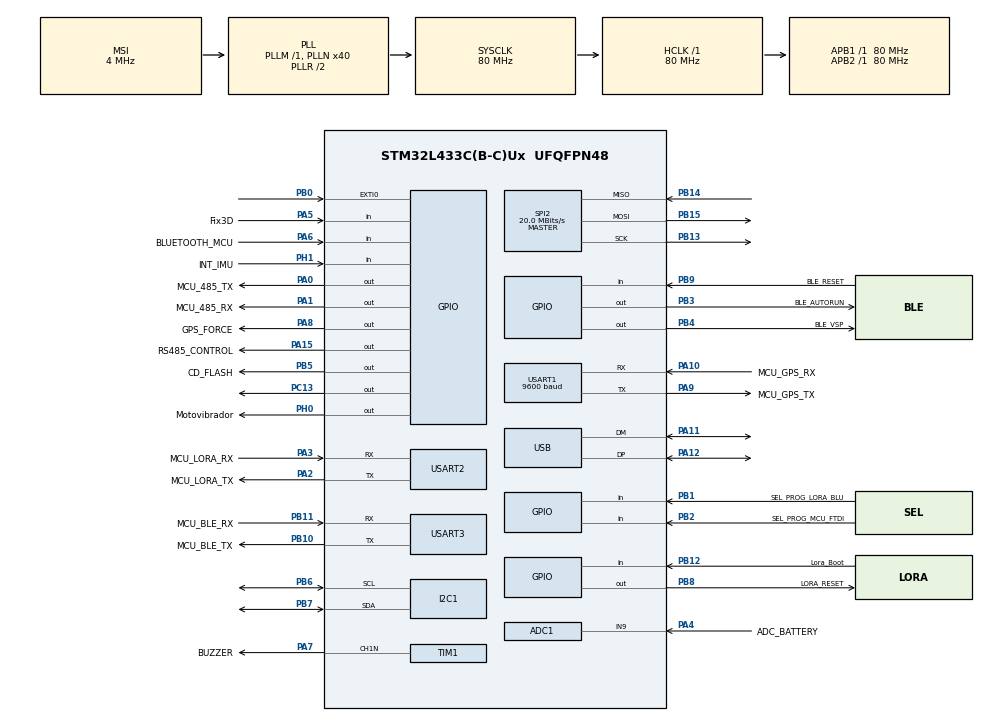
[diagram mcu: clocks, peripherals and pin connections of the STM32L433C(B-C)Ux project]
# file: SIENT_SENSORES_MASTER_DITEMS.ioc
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ADC1.Channel-1\#ChannelRegularConversion=ADC_CHANNEL_9
ADC1.NbrOfConversionFlag=1
ADC1.OffsetNumber-1\#ChannelRegularConversion=ADC_OFFSET_NONE
ADC1.Rank-1\#ChannelRegularConversion=1
ADC1.SamplingTime-1\#ChannelRegularConversion=ADC_SAMPLETIME_2CYCLES_5
ADC1.master=1
Dma.Request0=USART1_RX
Dma.Request1=USART2_RX
Dma.USART1_RX.0.Direction=DMA_PERIPH_TO_MEMORY
Dma.USART1_RX.0.Instance=DMA1_Channel5
Dma.USART1_RX.0.MemDataAlignment=DMA_MDATAALIGN_BYTE
Dma.USART1_RX.0.MemInc=DMA_MINC_ENABLE
Dma.USART1_RX.0.Mode=DMA_CIRCULAR
Dma.USART1_RX.0.PeriphDataAlignment=DMA_PDATAALIGN_BYTE
Dma.USART1_RX.0.PeriphInc=DMA_PINC_DISABLE
Dma.USART1_RX.0.Priority=DMA_PRIORITY_LOW
Dma.USART2_RX.1.Direction=DMA_PERIPH_TO_MEMORY
Dma.USART2_RX.1.Instance=DMA1_Channel6
Dma.USART2_RX.1.MemDataAlignment=DMA_MDATAALIGN_BYTE
Dma.USART2_RX.1.MemInc=DMA_MINC_ENABLE
Dma.USART2_RX.1.Mode=DMA_CIRCULAR
Dma.USART2_RX.1.PeriphDataAlignment=DMA_PDATAALIGN_BYTE
Dma.USART2_RX.1.PeriphInc=DMA_PINC_DISABLE
Dma.USART2_RX.1.Priority=DMA_PRIORITY_LOW
FREERTOS.Tasks01=defaultTask,24,128,StartDefaultTask,Default,NULL,Dynamic,NULL,NULL
FREERTOS.configTOTAL_HEAP_SIZE=16384
FREERTOS.configUSE_NEWLIB_REENTRANT=1
I2C1.Timing=0x10D19CE4
Mcu.Family=STM32L4
Mcu.Name=STM32L433C(B-C)Ux
Mcu.Package=UFQFPN48
NVIC.DMA1_Channel5_IRQn=true\:6\:0\:true\:false\:true\:true\:false\:true\:true
NVIC.DMA1_Channel6_IRQn=true\:5\:0\:false\:false\:true\:true\:false\:true\:true
NVIC.EXTI0_IRQn=true\:5\:0\:false\:false\:true\:false\:true\:true\:true
NVIC.PriorityGroup=NVIC_PRIORITYGROUP_4
NVIC.TIM7_IRQn=true\:15\:0\:false\:false\:true\:false\:false\:true\:true
NVIC.TimeBase=TIM7_IRQn
NVIC.TimeBaseIP=TIM7
NVIC.USART1_IRQn=true\:6\:0\:true\:false\:true\:true\:true\:true\:true
NVIC.USART2_IRQn=true\:5\:0\:false\:false\:true\:true\:true\:true\:true
NVIC.USART3_IRQn=true\:6\:0\:true\:false\:true\:true\:true\:true\:true
NVIC.USB_IRQn=true\:6\:0\:true\:false\:true\:true\:false\:true\:true
PA0.GPIO_Label=MCU_485_TX
PA0.Signal=GPIO_Output
PA1.GPIO_Label=MCU_485_RX
PA1.Signal=GPIO_Output
PA10.GPIO_Label=MCU_GPS_RX
PA10.Mode=Asynchronous
PA10.Signal=USART1_RX
PA11.Mode=Device
PA11.Signal=USB_DM
PA12.Mode=Device
PA12.Signal=USB_DP
PA13\ (JTMS-SWDIO).Mode=Serial_Wire
PA13\ (JTMS-SWDIO).Signal=SYS_JTMS-SWDIO
PA14\ (JTCK-SWCLK).Mode=Serial_Wire
PA14\ (JTCK-SWCLK).Signal=SYS_JTCK-SWCLK
PA15\ (JTDI).GPIO_Label=RS485_CONTROL
PA15\ (JTDI).Signal=GPIO_Output
PA2.GPIO_Label=MCU_LORA_TX
PA2.Mode=Asynchronous
PA2.Signal=USART2_TX
PA3.GPIO_Label=MCU_LORA_RX
PA3.Mode=Asynchronous
PA3.Signal=USART2_RX
PA4.GPIO_Label=ADC_BATTERY
PA4.Signal=ADCx_IN9
PA5.GPIO_Label=Fix3D
PA5.Signal=GPIO_Input
PA6.GPIO_Label=BLUETOOTH_MCU
PA6.Signal=GPIO_Input
PA7.GPIO_Label=BUZZER
PA7.Mode=PWM Generation1 CH1N
PA7.Signal=TIM1_CH1N
PA8.GPIO_Label=GPS_FORCE
PA8.Signal=GPIO_Output
PA9.GPIO_Label=MCU_GPS_TX
PA9.Mode=Asynchronous
PA9.Signal=USART1_TX
PB0.GPIO_ModeDefaultEXTI=GPIO_MODE_IT_RISING_FALLING
PB0.Signal=GPXTI0
PB1.GPIO_Label=SEL_PROG_LORA_BLU
PB1.Signal=GPIO_Input
PB10.GPIO_Label=MCU_BLE_TX
PB10.Mode=Asynchronous
PB10.Signal=USART3_TX
PB11.GPIO_Label=MCU_BLE_RX
PB11.Mode=Asynchronous
PB11.Signal=USART3_RX
PB12.GPIO_Label=Lora_Boot
PB12.Signal=GPIO_Input
PB13.Mode=Full_Duplex_Master
PB13.Signal=SPI2_SCK
PB14.Mode=Full_Duplex_Master
PB14.Signal=SPI2_MISO
PB15.Mode=Full_Duplex_Master
PB15.Signal=SPI2_MOSI
PB2.GPIO_Label=SEL_PROG_MCU_FTDI
PB2.Signal=GPIO_Input
PB3\ (JTDO-TRACESWO).GPIO_Label=BLE_AUTORUN
PB3\ (JTDO-TRACESWO).Signal=GPIO_Output
PB4\ (NJTRST).GPIO_Label=BLE_VSP
PB4\ (NJTRST).Signal=GPIO_Output
PB5.GPIO_Label=CD_FLASH
PB5.Signal=GPIO_Output
PB6.Mode=I2C
PB6.Signal=I2C1_SCL
PB7.Mode=I2C
PB7.Signal=I2C1_SDA
PB8.GPIO_Label=LORA_RESET
PB8.Signal=GPIO_Output
PB9.GPIO_Label=BLE_RESET
PB9.Signal=GPIO_Input
PC13.PinState=GPIO_PIN_SET
PC13.Signal=GPIO_Output
PC14-OSC32_IN\ (PC14).Mode=LSE-External-Oscillator
PC14-OSC32_IN\ (PC14).Signal=RCC_OSC32_IN
PC15-OSC32_OUT\ (PC15).Mode=LSE-External-Oscillator
PC15-OSC32_OUT\ (PC15).Signal=RCC_OSC32_OUT
PH0-OSC_IN\ (PH0).GPIO_Label=Motovibrador
PH0-OSC_IN\ (PH0).Signal=GPIO_Output
PH1-OSC_OUT\ (PH1).GPIO_Label=INT_IMU
PH1-OSC_OUT\ (PH1).Signal=GPIO_Input
ProjectManager.HeapSize=0x200
ProjectManager.StackSize=0x400
ProjectManager.TargetToolchain=STM32CubeIDE
RCC.ADCFreq_Value=48000000
RCC.AHBFreq_Value=80000000
RCC.APB1Freq_Value=80000000
RCC.APB1TimFreq_Value=80000000
RCC.APB2Freq_Value=80000000
RCC.APB2TimFreq_Value=80000000
RCC.CortexFreq_Value=80000000
RCC.HCLKFreq_Value=80000000
RCC.HSE_VALUE=8000000
RCC.HSI48_VALUE=48000000
RCC.HSI_VALUE=16000000
RCC.MSI_VALUE=4000000
RCC.PLLN=40
RCC.PLLSAI1N=24
RCC.SYSCLKFreq_VALUE=80000000
RCC.SYSCLKSource=RCC_SYSCLKSOURCE_PLLCLK
RCC.USBFreq_Value=48000000
RCC.VCOOutputFreq_Value=160000000
SH.ADCx_IN9.0=ADC1_IN9,IN9-Single-Ended
SPI2.BaudRatePrescaler=SPI_BAUDRATEPRESCALER_4
SPI2.CalculateBaudRate=20.0 MBits/s
SPI2.DataSize=SPI_DATASIZE_8BIT
SPI2.Direction=SPI_DIRECTION_2LINES
SPI2.Mode=SPI_MODE_MASTER
SPI2.VirtualType=VM_MASTER
TIM1.Channel-PWM\ Generation1\ CH1N=TIM_CHANNEL_1
TIM1.Prescaler=79
USART1.BaudRate=9600
USART1.VirtualMode-Asynchronous=VM_ASYNC
USART2.VirtualMode-Asynchronous=VM_ASYNC
USART3.VirtualMode-Asynchronous=VM_ASYNC
USB_DEVICE.CLASS_NAME_FS=CDC
USB_DEVICE.VirtualMode=Cdc
USB_DEVICE.VirtualModeFS=Cdc_FS
VP_FREERTOS_VS_CMSIS_V2.Mode=CMSIS_V2
VP_SYS_VS_tim7.Mode=TIM7
VP_TIM1_VS_ClockSourceINT.Mode=Internal
VP_USB_DEVICE_VS_USB_DEVICE_CDC_FS.Mode=CDC_FS
board=custom

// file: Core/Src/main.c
/* USER CODE BEGIN Header */
/**
  ******************************************************************************
  * @file           : main.c
  * @brief          : Main program body
  ******************************************************************************
  * @attention
  *
  * Copyright (c) 2026 STMicroelectronics.
  * All rights reserved.
  *
  * This software is licensed under terms that can be found in the LICENSE file
  * in the root directory of this software component.
  * If no LICENSE file comes with this software, it is provided AS-IS.
  *
  ******************************************************************************
  */
/* USER CODE END Header */
#include "main.h"
#include "cmsis_os.h"
#include "usb_device.h"

/* USER CODE BEGIN Includes */
#include "Inicializacion.h"
#include "Tareas.h"
#include "Test.h"
/* USER CODE END Includes */

ADC_HandleTypeDef hadc1;

I2C_HandleTypeDef hi2c1;

SPI_HandleTypeDef hspi2;

TIM_HandleTypeDef htim1;

UART_HandleTypeDef huart1;
UART_HandleTypeDef huart2;
UART_HandleTypeDef huart3;
DMA_HandleTypeDef hdma_usart1_rx;
DMA_HandleTypeDef hdma_usart2_rx;

void SystemClock_Config(void);
void PeriphCommonClock_Config(void);
static void MX_GPIO_Init(void);
static void MX_DMA_Init(void);
static void MX_ADC1_Init(void);
static void MX_I2C1_Init(void);
static void MX_SPI2_Init(void);
static void MX_TIM1_Init(void);
static void MX_USART1_UART_Init(void);
static void MX_USART2_UART_Init(void);
static void MX_USART3_UART_Init(void);

int main(void)
{

  /* MCU Configuration--------------------------------------------------------*/

  /* Reset of all peripherals, Initializes the Flash interface and the Systick. */
  HAL_Init();

  /* USER CODE BEGIN Init */

  /* DIAGNOSTICO: fuerza un reset completo del dominio RTC/backup al arrancar.
   * Sospecha: el pin WAKEUP del GPS (dominio RTC/Backup del modulo, ver
   * datasheet) se forzo en alto sostenido cuando debia quedar N/C — esta
   * tarjeta en particular dejo de poder entrar al bootloader USB de fabrica
   * (el Logger de la app SI sigue enumerando bien, pero ese usa un reloj USB
   * distinto al del bootloader ROM). Si el dominio backup de ESTE micro quedo
   * en un estado raro por esa maniobra, esto lo limpia. Quitar si no ayuda.
   */
  HAL_PWR_EnableBkUpAccess();
  __HAL_RCC_BACKUPRESET_FORCE();
  __HAL_RCC_BACKUPRESET_RELEASE();

  /* USER CODE END Init */

  /* Configure the system clock */
  SystemClock_Config();

  /* Configure the peripherals common clocks */
  PeriphCommonClock_Config();

  /* Initialize all configured peripherals */
  MX_GPIO_Init();
  MX_DMA_Init();
  MX_ADC1_Init();
  MX_I2C1_Init();
  MX_SPI2_Init();
  MX_TIM1_Init();
  MX_USART1_UART_Init();
  MX_USART2_UART_Init();
  MX_USART3_UART_Init();
  /* USER CODE BEGIN 2 */

  Inicializacion_Run();

  // Test_IR_Init();   /* PRUEBA IR — en pausa */

  /* USER CODE END 2 */

  /* Init scheduler */
  osKernelInitialize();

  /* USER CODE BEGIN RTOS_MUTEX */
  /* kernel inicializado, scheduler sin correr aun — seguro crear mutex aqui */
  Tareas_InicializarMutex();
  /* USER CODE END RTOS_MUTEX */

  /* Create the thread(s) */
  /* USER CODE BEGIN RTOS_THREADS */
  Tareas_CrearTareas();
  /* USER CODE END RTOS_THREADS */

  /* Start scheduler */
  osKernelStart();

  /* We should never get here as control is now taken by the scheduler */

  /* Infinite loop */
  while (1)
  {

    /* USER CODE BEGIN 3 */
    // Test_IR_Poll();   /* PRUEBA IR — en pausa */
  }
  /* USER CODE END 3 */
}

void SystemClock_Config(void)
{
  RCC_OscInitTypeDef RCC_OscInitStruct = {0};
  RCC_ClkInitTypeDef RCC_ClkInitStruct = {0};

  /** Configure the main internal regulator output voltage
  */
  if (HAL_PWREx_ControlVoltageScaling(PWR_REGULATOR_VOLTAGE_SCALE1) != HAL_OK)
  {
    Error_Handler();
  }

  /** Configure LSE Drive Capability
  */
  HAL_PWR_EnableBkUpAccess();
  __HAL_RCC_LSEDRIVE_CONFIG(RCC_LSEDRIVE_LOW);

  /** Initializes the RCC Oscillators according to the specified parameters
  * in the RCC_OscInitTypeDef structure.
  */
  RCC_OscInitStruct.OscillatorType = RCC_OSCILLATORTYPE_LSE|RCC_OSCILLATORTYPE_MSI;
  RCC_OscInitStruct.LSEState = RCC_LSE_ON;
  RCC_OscInitStruct.MSIState = RCC_MSI_ON;
  RCC_OscInitStruct.MSICalibrationValue = 0;
  RCC_OscInitStruct.MSIClockRange = RCC_MSIRANGE_6;
  RCC_OscInitStruct.PLL.PLLState = RCC_PLL_ON;
  RCC_OscInitStruct.PLL.PLLSource = RCC_PLLSOURCE_MSI;
  RCC_OscInitStruct.PLL.PLLM = 1;
  RCC_OscInitStruct.PLL.PLLN = 40;
  RCC_OscInitStruct.PLL.PLLP = RCC_PLLP_DIV7;
  RCC_OscInitStruct.PLL.PLLQ = RCC_PLLQ_DIV2;
  RCC_OscInitStruct.PLL.PLLR = RCC_PLLR_DIV2;
  if (HAL_RCC_OscConfig(&RCC_OscInitStruct) != HAL_OK)
  {
    Error_Handler();
  }

  /** Initializes the CPU, AHB and APB buses clocks
  */
  RCC_ClkInitStruct.ClockType = RCC_CLOCKTYPE_HCLK|RCC_CLOCKTYPE_SYSCLK
                              |RCC_CLOCKTYPE_PCLK1|RCC_CLOCKTYPE_PCLK2;
  RCC_ClkInitStruct.SYSCLKSource = RCC_SYSCLKSOURCE_PLLCLK;
  RCC_ClkInitStruct.AHBCLKDivider = RCC_SYSCLK_DIV1;
  RCC_ClkInitStruct.APB1CLKDivider = RCC_HCLK_DIV1;
  RCC_ClkInitStruct.APB2CLKDivider = RCC_HCLK_DIV1;

  if (HAL_RCC_ClockConfig(&RCC_ClkInitStruct, FLASH_LATENCY_4) != HAL_OK)
  {
    Error_Handler();
  }

  /** Enable MSI Auto calibration
  */
  HAL_RCCEx_EnableMSIPLLMode();
}

void PeriphCommonClock_Config(void)
{
  RCC_PeriphCLKInitTypeDef PeriphClkInit = {0};

  /** Initializes the peripherals clock
  */
  PeriphClkInit.PeriphClockSelection = RCC_PERIPHCLK_USB|RCC_PERIPHCLK_ADC;
  PeriphClkInit.AdcClockSelection = RCC_ADCCLKSOURCE_PLLSAI1;
  PeriphClkInit.UsbClockSelection = RCC_USBCLKSOURCE_PLLSAI1;
  PeriphClkInit.PLLSAI1.PLLSAI1Source = RCC_PLLSOURCE_MSI;
  PeriphClkInit.PLLSAI1.PLLSAI1M = 1;
  PeriphClkInit.PLLSAI1.PLLSAI1N = 24;
  PeriphClkInit.PLLSAI1.PLLSAI1P = RCC_PLLP_DIV7;
  PeriphClkInit.PLLSAI1.PLLSAI1Q = RCC_PLLQ_DIV2;
  PeriphClkInit.PLLSAI1.PLLSAI1R = RCC_PLLR_DIV2;
  PeriphClkInit.PLLSAI1.PLLSAI1ClockOut = RCC_PLLSAI1_48M2CLK|RCC_PLLSAI1_ADC1CLK;
  if (HAL_RCCEx_PeriphCLKConfig(&PeriphClkInit) != HAL_OK)
  {
    Error_Handler();
  }
}

static void MX_ADC1_Init(void)
{

  ADC_ChannelConfTypeDef sConfig = {0};

  /** Common config
  */
  hadc1.Instance = ADC1;
  hadc1.Init.ClockPrescaler = ADC_CLOCK_ASYNC_DIV1;
  hadc1.Init.Resolution = ADC_RESOLUTION_12B;
  hadc1.Init.DataAlign = ADC_DATAALIGN_RIGHT;
  hadc1.Init.ScanConvMode = ADC_SCAN_DISABLE;
  hadc1.Init.EOCSelection = ADC_EOC_SINGLE_CONV;
  hadc1.Init.LowPowerAutoWait = DISABLE;
  hadc1.Init.ContinuousConvMode = DISABLE;
  hadc1.Init.NbrOfConversion = 1;
  hadc1.Init.DiscontinuousConvMode = DISABLE;
  hadc1.Init.ExternalTrigConv = ADC_SOFTWARE_START;
  hadc1.Init.ExternalTrigConvEdge = ADC_EXTERNALTRIGCONVEDGE_NONE;
  hadc1.Init.DMAContinuousRequests = DISABLE;
  hadc1.Init.Overrun = ADC_OVR_DATA_PRESERVED;
  hadc1.Init.OversamplingMode = DISABLE;
  if (HAL_ADC_Init(&hadc1) != HAL_OK)
  {
    Error_Handler();
  }

  /** Configure Regular Channel
  */
  sConfig.Channel = ADC_CHANNEL_9;
  sConfig.Rank = ADC_REGULAR_RANK_1;
  sConfig.SamplingTime = ADC_SAMPLETIME_2CYCLES_5;
  sConfig.SingleDiff = ADC_SINGLE_ENDED;
  sConfig.OffsetNumber = ADC_OFFSET_NONE;
  sConfig.Offset = 0;
  if (HAL_ADC_ConfigChannel(&hadc1, &sConfig) != HAL_OK)
  {
    Error_Handler();
  }

}

static void MX_I2C1_Init(void)
{

  hi2c1.Instance = I2C1;
  hi2c1.Init.Timing = 0x10D19CE4;
  hi2c1.Init.OwnAddress1 = 0;
  hi2c1.Init.AddressingMode = I2C_ADDRESSINGMODE_7BIT;
  hi2c1.Init.DualAddressMode = I2C_DUALADDRESS_DISABLE;
  hi2c1.Init.OwnAddress2 = 0;
  hi2c1.Init.OwnAddress2Masks = I2C_OA2_NOMASK;
  hi2c1.Init.GeneralCallMode = I2C_GENERALCALL_DISABLE;
  hi2c1.Init.NoStretchMode = I2C_NOSTRETCH_DISABLE;
  if (HAL_I2C_Init(&hi2c1) != HAL_OK)
  {
    Error_Handler();
  }

  /** Configure Analogue filter
  */
  if (HAL_I2CEx_ConfigAnalogFilter(&hi2c1, I2C_ANALOGFILTER_ENABLE) != HAL_OK)
  {
    Error_Handler();
  }

  /** Configure Digital filter
  */
  if (HAL_I2CEx_ConfigDigitalFilter(&hi2c1, 0) != HAL_OK)
  {
    Error_Handler();
  }

}

static void MX_SPI2_Init(void)
{

  /* SPI2 parameter configuration*/
  hspi2.Instance = SPI2;
  hspi2.Init.Mode = SPI_MODE_MASTER;
  hspi2.Init.Direction = SPI_DIRECTION_2LINES;
  hspi2.Init.DataSize = SPI_DATASIZE_8BIT;
  hspi2.Init.CLKPolarity = SPI_POLARITY_LOW;
  hspi2.Init.CLKPhase = SPI_PHASE_1EDGE;
  hspi2.Init.NSS = SPI_NSS_SOFT;
  hspi2.Init.BaudRatePrescaler = SPI_BAUDRATEPRESCALER_4;
  hspi2.Init.FirstBit = SPI_FIRSTBIT_MSB;
  hspi2.Init.TIMode = SPI_TIMODE_DISABLE;
  hspi2.Init.CRCCalculation = SPI_CRCCALCULATION_DISABLE;
  hspi2.Init.CRCPolynomial = 7;
  hspi2.Init.CRCLength = SPI_CRC_LENGTH_DATASIZE;
  hspi2.Init.NSSPMode = SPI_NSS_PULSE_ENABLE;
  if (HAL_SPI_Init(&hspi2) != HAL_OK)
  {
    Error_Handler();
  }

}

static void MX_TIM1_Init(void)
{

  TIM_ClockConfigTypeDef sClockSourceConfig = {0};
  TIM_MasterConfigTypeDef sMasterConfig = {0};
  TIM_OC_InitTypeDef sConfigOC = {0};
  TIM_BreakDeadTimeConfigTypeDef sBreakDeadTimeConfig = {0};

  htim1.Instance = TIM1;
  htim1.Init.Prescaler = 79;
  htim1.Init.CounterMode = TIM_COUNTERMODE_UP;
  htim1.Init.Period = 65535;
  htim1.Init.ClockDivision = TIM_CLOCKDIVISION_DIV1;
  htim1.Init.RepetitionCounter = 0;
  htim1.Init.AutoReloadPreload = TIM_AUTORELOAD_PRELOAD_DISABLE;
  if (HAL_TIM_Base_Init(&htim1) != HAL_OK)
  {
    Error_Handler();
  }
  sClockSourceConfig.ClockSource = TIM_CLOCKSOURCE_INTERNAL;
  if (HAL_TIM_ConfigClockSource(&htim1, &sClockSourceConfig) != HAL_OK)
  {
    Error_Handler();
  }
  if (HAL_TIM_PWM_Init(&htim1) != HAL_OK)
  {
    Error_Handler();
  }
  sMasterConfig.MasterOutputTrigger = TIM_TRGO_RESET;
  sMasterConfig.MasterOutputTrigger2 = TIM_TRGO2_RESET;
  sMasterConfig.MasterSlaveMode = TIM_MASTERSLAVEMODE_DISABLE;
  if (HAL_TIMEx_MasterConfigSynchronization(&htim1, &sMasterConfig) != HAL_OK)
  {
    Error_Handler();
  }
  sConfigOC.OCMode = TIM_OCMODE_PWM1;
  sConfigOC.Pulse = 0;
  sConfigOC.OCPolarity = TIM_OCPOLARITY_HIGH;
  sConfigOC.OCNPolarity = TIM_OCNPOLARITY_HIGH;
  sConfigOC.OCFastMode = TIM_OCFAST_DISABLE;
  sConfigOC.OCIdleState = TIM_OCIDLESTATE_RESET;
  sConfigOC.OCNIdleState = TIM_OCNIDLESTATE_RESET;
  if (HAL_TIM_PWM_ConfigChannel(&htim1, &sConfigOC, TIM_CHANNEL_1) != HAL_OK)
  {
    Error_Handler();
  }
  sBreakDeadTimeConfig.OffStateRunMode = TIM_OSSR_DISABLE;
  sBreakDeadTimeConfig.OffStateIDLEMode = TIM_OSSI_DISABLE;
  sBreakDeadTimeConfig.LockLevel = TIM_LOCKLEVEL_OFF;
  sBreakDeadTimeConfig.DeadTime = 0;
  sBreakDeadTimeConfig.BreakState = TIM_BREAK_DISABLE;
  sBreakDeadTimeConfig.BreakPolarity = TIM_BREAKPOLARITY_HIGH;
  sBreakDeadTimeConfig.BreakFilter = 0;
  sBreakDeadTimeConfig.Break2State = TIM_BREAK2_DISABLE;
  sBreakDeadTimeConfig.Break2Polarity = TIM_BREAK2POLARITY_HIGH;
  sBreakDeadTimeConfig.Break2Filter = 0;
  sBreakDeadTimeConfig.AutomaticOutput = TIM_AUTOMATICOUTPUT_DISABLE;
  if (HAL_TIMEx_ConfigBreakDeadTime(&htim1, &sBreakDeadTimeConfig) != HAL_OK)
  {
    Error_Handler();
  }
  HAL_TIM_MspPostInit(&htim1);

}

static void MX_USART1_UART_Init(void)
{

  huart1.Instance = USART1;
  huart1.Init.BaudRate = 9600;
  huart1.Init.WordLength = UART_WORDLENGTH_8B;
  huart1.Init.StopBits = UART_STOPBITS_1;
  huart1.Init.Parity = UART_PARITY_NONE;
  huart1.Init.Mode = UART_MODE_TX_RX;
  huart1.Init.HwFlowCtl = UART_HWCONTROL_NONE;
  huart1.Init.OverSampling = UART_OVERSAMPLING_16;
  huart1.Init.OneBitSampling = UART_ONE_BIT_SAMPLE_DISABLE;
  huart1.AdvancedInit.AdvFeatureInit = UART_ADVFEATURE_NO_INIT;
  if (HAL_UART_Init(&huart1) != HAL_OK)
  {
    Error_Handler();
  }

}

static void MX_USART2_UART_Init(void)
{

  huart2.Instance = USART2;
  huart2.Init.BaudRate = 115200;
  huart2.Init.WordLength = UART_WORDLENGTH_8B;
  huart2.Init.StopBits = UART_STOPBITS_1;
  huart2.Init.Parity = UART_PARITY_NONE;
  huart2.Init.Mode = UART_MODE_TX_RX;
  huart2.Init.HwFlowCtl = UART_HWCONTROL_NONE;
  huart2.Init.OverSampling = UART_OVERSAMPLING_16;
  huart2.Init.OneBitSampling = UART_ONE_BIT_SAMPLE_DISABLE;
  huart2.AdvancedInit.AdvFeatureInit = UART_ADVFEATURE_NO_INIT;
  if (HAL_UART_Init(&huart2) != HAL_OK)
  {
    Error_Handler();
  }

}

static void MX_USART3_UART_Init(void)
{

  huart3.Instance = USART3;
  huart3.Init.BaudRate = 115200;
  huart3.Init.WordLength = UART_WORDLENGTH_8B;
  huart3.Init.StopBits = UART_STOPBITS_1;
  huart3.Init.Parity = UART_PARITY_NONE;
  huart3.Init.Mode = UART_MODE_TX_RX;
  huart3.Init.HwFlowCtl = UART_HWCONTROL_NONE;
  huart3.Init.OverSampling = UART_OVERSAMPLING_16;
  huart3.Init.OneBitSampling = UART_ONE_BIT_SAMPLE_DISABLE;
  huart3.AdvancedInit.AdvFeatureInit = UART_ADVFEATURE_NO_INIT;
  if (HAL_UART_Init(&huart3) != HAL_OK)
  {
    Error_Handler();
  }

}

static void MX_DMA_Init(void)
{

  /* DMA controller clock enable */
  __HAL_RCC_DMA1_CLK_ENABLE();

  /* DMA interrupt init */
  /* DMA1_Channel5_IRQn interrupt configuration */
  HAL_NVIC_SetPriority(DMA1_Channel5_IRQn, 6, 0);
  HAL_NVIC_EnableIRQ(DMA1_Channel5_IRQn);
  /* DMA1_Channel6_IRQn interrupt configuration */
  HAL_NVIC_SetPriority(DMA1_Channel6_IRQn, 5, 0);
  HAL_NVIC_EnableIRQ(DMA1_Channel6_IRQn);

}

static void MX_GPIO_Init(void)
{
  GPIO_InitTypeDef GPIO_InitStruct = {0};

  /* GPIO Ports Clock Enable */
  __HAL_RCC_GPIOC_CLK_ENABLE();
  __HAL_RCC_GPIOH_CLK_ENABLE();
  __HAL_RCC_GPIOA_CLK_ENABLE();
  __HAL_RCC_GPIOB_CLK_ENABLE();

  /*Configure GPIO pin Output Level */
  HAL_GPIO_WritePin(GPIOC, GPIO_PIN_13, GPIO_PIN_SET);

  /*Configure GPIO pin Output Level */
  HAL_GPIO_WritePin(Motovibrador_GPIO_Port, Motovibrador_Pin, GPIO_PIN_RESET);

  /*Configure GPIO pin Output Level */
  HAL_GPIO_WritePin(GPIOA, MCU_485_TX_Pin|MCU_485_RX_Pin|GPS_FORCE_Pin|RS485_CONTROL_Pin, GPIO_PIN_RESET);

  /*Configure GPIO pin Output Level */
  HAL_GPIO_WritePin(GPIOB, BLE_AUTORUN_Pin|BLE_VSP_Pin|CD_FLASH_Pin|LORA_RESET_Pin, GPIO_PIN_RESET);

  /*Configure GPIO pin : PC13 */
  GPIO_InitStruct.Pin = GPIO_PIN_13;
  GPIO_InitStruct.Mode = GPIO_MODE_OUTPUT_PP;
  GPIO_InitStruct.Pull = GPIO_NOPULL;
  GPIO_InitStruct.Speed = GPIO_SPEED_FREQ_LOW;
  HAL_GPIO_Init(GPIOC, &GPIO_InitStruct);

  /*Configure GPIO pin : Motovibrador_Pin */
  GPIO_InitStruct.Pin = Motovibrador_Pin;
  GPIO_InitStruct.Mode = GPIO_MODE_OUTPUT_PP;
  GPIO_InitStruct.Pull = GPIO_NOPULL;
  GPIO_InitStruct.Speed = GPIO_SPEED_FREQ_LOW;
  HAL_GPIO_Init(Motovibrador_GPIO_Port, &GPIO_InitStruct);

  /*Configure GPIO pin : INT_IMU_Pin */
  GPIO_InitStruct.Pin = INT_IMU_Pin;
  GPIO_InitStruct.Mode = GPIO_MODE_INPUT;
  GPIO_InitStruct.Pull = GPIO_NOPULL;
  HAL_GPIO_Init(INT_IMU_GPIO_Port, &GPIO_InitStruct);

  /*Configure GPIO pins : MCU_485_TX_Pin MCU_485_RX_Pin GPS_FORCE_Pin RS485_CONTROL_Pin */
  GPIO_InitStruct.Pin = MCU_485_TX_Pin|MCU_485_RX_Pin|GPS_FORCE_Pin|RS485_CONTROL_Pin;
  GPIO_InitStruct.Mode = GPIO_MODE_OUTPUT_PP;
  GPIO_InitStruct.Pull = GPIO_NOPULL;
  GPIO_InitStruct.Speed = GPIO_SPEED_FREQ_LOW;
  HAL_GPIO_Init(GPIOA, &GPIO_InitStruct);

  /*Configure GPIO pins : Fix3D_Pin BLUETOOTH_MCU_Pin */
  GPIO_InitStruct.Pin = Fix3D_Pin|BLUETOOTH_MCU_Pin;
  GPIO_InitStruct.Mode = GPIO_MODE_INPUT;
  GPIO_InitStruct.Pull = GPIO_NOPULL;
  HAL_GPIO_Init(GPIOA, &GPIO_InitStruct);

  /*Configure GPIO pin : PB0 */
  GPIO_InitStruct.Pin = GPIO_PIN_0;
  GPIO_InitStruct.Mode = GPIO_MODE_IT_RISING_FALLING;
  GPIO_InitStruct.Pull = GPIO_NOPULL;
  HAL_GPIO_Init(GPIOB, &GPIO_InitStruct);

  /*Configure GPIO pins : SEL_PROG_LORA_BLU_Pin SEL_PROG_MCU_FTDI_Pin Lora_Boot_Pin BLE_RESET_Pin */
  GPIO_InitStruct.Pin = SEL_PROG_LORA_BLU_Pin|SEL_PROG_MCU_FTDI_Pin|Lora_Boot_Pin|BLE_RESET_Pin;
  GPIO_InitStruct.Mode = GPIO_MODE_INPUT;
  GPIO_InitStruct.Pull = GPIO_NOPULL;
  HAL_GPIO_Init(GPIOB, &GPIO_InitStruct);

  /*Configure GPIO pins : BLE_AUTORUN_Pin BLE_VSP_Pin CD_FLASH_Pin LORA_RESET_Pin */
  GPIO_InitStruct.Pin = BLE_AUTORUN_Pin|BLE_VSP_Pin|CD_FLASH_Pin|LORA_RESET_Pin;
  GPIO_InitStruct.Mode = GPIO_MODE_OUTPUT_PP;
  GPIO_InitStruct.Pull = GPIO_NOPULL;
  GPIO_InitStruct.Speed = GPIO_SPEED_FREQ_LOW;
  HAL_GPIO_Init(GPIOB, &GPIO_InitStruct);

  /* EXTI interrupt init*/
  HAL_NVIC_SetPriority(EXTI0_IRQn, 5, 0);
  HAL_NVIC_EnableIRQ(EXTI0_IRQn);

}

/* USER CODE BEGIN 4 */

/* HAL_GPIO_EXTI_Callback(), HAL_UART_RxCpltCallback() y
 * HAL_UART_ErrorCallback() viven en Inicializacion.c (GPS/IR ya son parte
 * del arranque real). No redefinirlos aqui — un solo weak override por
 * funcion en todo el link. */

/* USER CODE END 4 */

void HAL_TIM_PeriodElapsedCallback(TIM_HandleTypeDef *htim)
{
  if (htim->Instance == TIM7)
  {
    HAL_IncTick();
  }
}

void Error_Handler(void)
{
  __disable_irq();
  while (1)
  {
  }
}

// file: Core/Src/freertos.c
/* USER CODE BEGIN Header */
/**
  ******************************************************************************
  * File Name          : freertos.c
  * Description        : Code for freertos applications
  ******************************************************************************
  * @attention
  *
  * Copyright (c) 2026 STMicroelectronics.
  * All rights reserved.
  *
  * This software is licensed under terms that can be found in the LICENSE file
  * in the root directory of this software component.
  * If no LICENSE file comes with this software, it is provided AS-IS.
  *
  ******************************************************************************
  */
/* USER CODE END Header */

#include "FreeRTOS.h"
#include "task.h"
#include "main.h"

/* USER CODE BEGIN Variables */

/* Guardados para inspeccionar con el debugger tras un stack overflow — el
 * HardFault_Handler default es un while(1) mudo, sin esto un overflow se ve
 * exactamente como el sistema muerto/sin logs, sin pista de la causa. */
static volatile char        s_overflow_task_name[configMAX_TASK_NAME_LEN];

/* USER CODE END Variables */

/* USER CODE BEGIN Application */

/**
 * @brief  FreeRTOS llama esto cuando detecta que una tarea se paso de su
 *         stack (configCHECK_FOR_STACK_OVERFLOW=2, ver FreeRTOSConfig.h).
 * @note   No se llama Log_Print aqui: el stack de la tarea que reboso ya
 *         esta corrupto, cualquier trabajo extra (mutex, printf) puede
 *         terminar de tronar todo. Solo guardamos el nombre y nos quedamos
 *         en un while(1) para poder pausar con el debugger y ver
 *         s_overflow_task_name / pxCurrentTCB.
 */
void vApplicationStackOverflowHook(TaskHandle_t xTask, char *pcTaskName)
{
    (void)xTask;
    for (uint8_t i = 0U; i < (configMAX_TASK_NAME_LEN - 1U) && pcTaskName[i] != '\0'; i++) {
        s_overflow_task_name[i] = pcTaskName[i];
    }
    __disable_irq();
    for (;;) {
        __NOP();
    }
}

/* USER CODE END Application */
